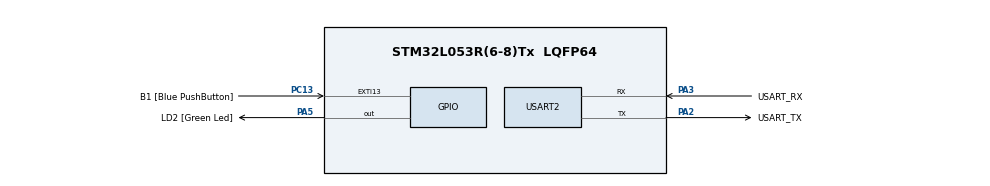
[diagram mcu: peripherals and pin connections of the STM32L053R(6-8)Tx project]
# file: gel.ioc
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Mcu.Family=STM32L0
RCC.MSI_VALUE=2097000
PC15-OSC32_OUT.Mode=LSE-External-Oscillator
PH0-OSC_IN.Signal=RCC_OSC_IN
PC13.Signal=GPXTI13
PA14.GPIO_Label=TCK
PC13.GPIO_Label=B1 [Blue PushButton]
PC14-OSC32_IN.Signal=RCC_OSC32_IN
ProjectManager.StackSize=0x400
PA3.Mode=Asynchronous
PA13.Signal=SYS_SWDIO
RCC.HSI16_VALUE=16000000
ProjectManager.TargetToolchain=STM32CubeIDE
RCC.APB2TimFreq_Value=2097000
PC15-OSC32_OUT.Signal=RCC_OSC32_OUT
RCC.AHBFreq_Value=2097000
PH0-OSC_IN.Mode=HSE-External-Clock-Source
PA5.Signal=GPIO_Output
RCC.HSE_VALUE=8000000
board=NUCLEO-L053R8
USART2.VirtualMode-Asynchronous=VM_ASYNC
RCC.VCOOutputFreq_Value=48000000
RCC.APB2Freq_Value=2097000
PC14-OSC32_IN.Mode=LSE-External-Oscillator
PA14.Mode=Serial_Wire
PH1-OSC_OUT.Signal=RCC_OSC_OUT
PA13.Mode=Serial_Wire
Mcu.Name=STM32L053R(6-8)Tx
PA2.Signal=USART2_TX
PA13.GPIO_Label=TMS
RCC.SYSCLKFreq_VALUE=2097000
Mcu.Package=LQFP64
PA5.GPIO_Label=LD2 [Green Led]
PC13.GPIO_ModeDefaultEXTI=GPIO_MODE_IT_FALLING
PA2.GPIO_Label=USART_TX
PA14.Signal=SYS_SWCLK
ProjectManager.HeapSize=0x200
RCC.HSI_VALUE=16000000
RCC.APB1TimFreq_Value=2097000
PA2.Mode=Asynchronous
RCC.APB1Freq_Value=2097000
RCC.HSI48_VALUE=48000000
PA3.GPIO_Label=USART_RX
PA3.Signal=USART2_RX

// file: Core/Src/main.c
/* USER CODE BEGIN Header */
/**
  ******************************************************************************
  * @file           : main.c
  * @brief          : Main program body
  ******************************************************************************
  * @attention
  *
  * <h2><center>&copy; Copyright (c) 2021 STMicroelectronics.
  * All rights reserved.</center></h2>
  *
  * This software component is licensed by ST under BSD 3-Clause license,
  * the "License"; You may not use this file except in compliance with the
  * License. You may obtain a copy of the License at:
  *                        opensource.org/licenses/BSD-3-Clause
  *
  ******************************************************************************
  */
/* USER CODE END Header */
#include "main.h"
#include "usart.h"
#include "gpio.h"
#include "lcd.h"

void SystemClock_Config(void);

void AlternateFunction(GPIO_TypeDef * port, uint8_t pin, uint8_t af);
void PWM(TIM_TypeDef * timer, uint8_t canal, uint32_t HCLKFrequency, uint32_t PWMFrequency ,float duty_cycle);
int _write(int file,char * ptr, int len)
{
for (int i=0; i<len;i++)
{
while(LL_USART_IsActiveFlag_TXE(USART2)==0);
LL_USART_TransmitData8(USART2,*ptr);
ptr++;
}
return len;
}

double distance = 0;

void ultrason()
{
	distance = 0;

		GPIOA->ODR|=(1<<1);  // activation du trig
		LL_mDelay(10); // delai d'activation
		GPIOA->ODR &=~(1<<1); // desactivation

		while((GPIOA->IDR & (1<<4)) == 0)  // attendre que le echo passe à 0
		{

		}

		while(GPIOA->IDR & (1<<4))
		{
			LL_mDelay(58);
			distance = distance +1 ; // calcule de la distance
		}

		printf("distance : %f\n", distance); // affichage de la distance
		buzzer();
		LL_mDelay(100000);

}

void buzzer(){

	if(distance > 10){
		GPIOA->ODR  &= ~(1<<0); // desactivation du buzzer si la distance du echo est inferieur à 10 cm
		lcdinit4();
		char ligne1[20] = "desinfectez vous"; // meessage a afficher ligne 1
		char ligne2[20] = "les mains svpl"; // meessage a afficher ligne 2
		Affichage_LCD(ligne1, ligne2);

	}else{

		GPIOA->ODR  |= (1<<0);// sactivation du buzzer si la distance du echo est inferieur à 10 cm
		LL_mDelay(30000);// delai d'activation
		GPIOA->ODR  &= ~(1<<0);// desactivation d
		lcdinit4();

		char ligne3[20] = "Merci";
		char ligne4[20] = "";
		Affichage_LCD(ligne3, ligne4);
		for(int i = 0;i<1500;i++){
				AlternateFunction(GPIOC, 7,0);
				PWM(TIM22, 2, 16000000, 15,0.125);
			   LL_mDelay(100);
			   PWM(TIM22, 2, 16000000, 15,0.125);
			   LL_mDelay(100);
		}

	}

}

int main(void)
{

	RCC->IOPENR |= RCC_IOPENR_GPIOAEN | RCC_IOPENR_GPIOBEN;

	GPIOA->MODER&=~(0b11<<(2*1));
	GPIOA->MODER|=(0b01<<(2*1)); //trig output

	GPIOA->MODER&=~(0b11<<(2*4)); //echo input
	GPIOA->MODER&=~(0b11<<(2*0));
	GPIOA->MODER |= (0b01<<(2*0));

  /* MCU Configuration--------------------------------------------------------*/

  /* Reset of all peripherals, Initializes the Flash interface and the Systick. */

  LL_APB2_GRP1_EnableClock(LL_APB2_GRP1_PERIPH_SYSCFG);
  LL_APB1_GRP1_EnableClock(LL_APB1_GRP1_PERIPH_PWR);

  /* System interrupt init*/

  /* Configure the system clock */
  SystemClock_Config();

  /* Initialize all configured peripherals */
  MX_GPIO_Init();
  MX_USART2_UART_Init();

  /* Infinite loop */
  /* USER CODE BEGIN WHILE */
  LL_Init1msTick(16000);
  while (1)
  {
    /* USER CODE END WHILE */

	   ultrason();
  }
}

void SystemClock_Config(void)
{
  LL_FLASH_SetLatency(LL_FLASH_LATENCY_0);
  while(LL_FLASH_GetLatency()!= LL_FLASH_LATENCY_0)
  {
  }
  LL_PWR_SetRegulVoltageScaling(LL_PWR_REGU_VOLTAGE_SCALE1);
  LL_RCC_MSI_Enable();

   /* Wait till MSI is ready */
  while(LL_RCC_MSI_IsReady() != 1)
  {

  }
  LL_RCC_MSI_SetRange(LL_RCC_MSIRANGE_5);
  LL_RCC_MSI_SetCalibTrimming(0);
  LL_RCC_SetAHBPrescaler(LL_RCC_SYSCLK_DIV_1);
  LL_RCC_SetAPB1Prescaler(LL_RCC_APB1_DIV_1);
  LL_RCC_SetAPB2Prescaler(LL_RCC_APB2_DIV_1);
  LL_RCC_SetSysClkSource(LL_RCC_SYS_CLKSOURCE_MSI);

   /* Wait till System clock is ready */
  while(LL_RCC_GetSysClkSource() != LL_RCC_SYS_CLKSOURCE_STATUS_MSI)
  {

  }

  LL_Init1msTick(2097000);

  LL_SetSystemCoreClock(2097000);
  LL_RCC_SetUSARTClockSource(LL_RCC_USART2_CLKSOURCE_PCLK1);
}

void Error_Handler(void)
{
  __disable_irq();
  while (1)
  {
  }
}

/************************ (C) COPYRIGHT STMicroelectronics *****END OF FILE****/
